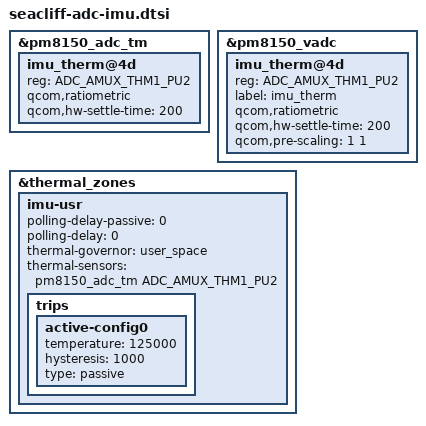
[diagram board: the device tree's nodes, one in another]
// SPDX-License-Identifier: GPL-2.0

&pm8150_adc_tm {
	imu_therm@4d {
		reg = <ADC_AMUX_THM1_PU2>;
		qcom,ratiometric;
		qcom,hw-settle-time = <200>;
	};
};

&pm8150_vadc {
	imu_therm@4d {
		reg = <ADC_AMUX_THM1_PU2>;
		label = "imu_therm";
		qcom,ratiometric;
		qcom,hw-settle-time = <200>;
		qcom,pre-scaling = <1 1>;
	};
};

&thermal_zones {
	imu-usr {
		polling-delay-passive = <0>;
		polling-delay = <0>;
		thermal-governor = "user_space";
		thermal-sensors = <&pm8150_adc_tm ADC_AMUX_THM1_PU2>;
		trips {
			active-config0 {
				temperature = <125000>;
				hysteresis = <1000>;
				type = "passive";
			};
		};
	};
};
